# TC37XPD register map
Vendor: Infineon; Series: ATVMC; File version: 100
CPU: other r0p0, little endian, MPU, FPU, vendor SysTick, 4 interrupt priority bits
Registers are 32-bit, read-write, reset 0x0 unless marked. A register's access mark holds for its fields unless they carry their own. Offsets are from the block's base; [hi:lo] are bit positions; {n}, {i} and the like mark numbered series.

## GETH (part 5 of 7)
Base 0xF001D000
0x810 RXIPV4_GOOD_PACKETS ro — Good Received RxIPv4 Packets Count Register resetvalue={Application Reset:0x0}
  [15:0] RXIPV4GDPKT — RxIPv4 Good Packets RXIPV4GDPKT. This field indicates the number of good IPv4 datagrams received with the TCP UDP or ICMP payload. Value After Reset 0x0
0x814 RXIPV4_HEADER_ERROR_PACKETS ro — Received IPv4 Header Error Packets Count Register resetvalue={Application Reset:0x0}
  [15:0] RXIPV4HDRERRPKT — RxIPv4 Header Error Packets RXIPV4HDRERRPKT. This field indicates the number of IPv4 datagrams received with header checksum length or version mismatch errors. Value After Reset 0x0
0x818 RXIPV4_NO_PAYLOAD_PACKETS ro — Received IPv4 No Payload Packets Count Register resetvalue={Application Reset:0x0}
  [15:0] RXIPV4NOPAYPKT — RxIPv4 Payload Packets RXIPV4NOPAYPKT. This field indicates the number of IPv4 datagram packets received that did not have a TCP UDP or ICMP payload. Value After Reset 0x0
0x81C RXIPV4_FRAGMENTED_PACKETS ro — Received IPv4 Fragmented Packets Count Register resetvalue={Application Reset:0x0}
  [15:0] RXIPV4FRAGPKT — RxIPv4 Fragmented Packets RXIPV4FRAGPKT. This field indicates the number of good IPv4 datagrams received with fragmentation. Value After Reset 0x0
0x820 RXIPV4_UDP_CHECKSUM_DISABLED_PACKETS ro — Received IPv4 UPD Checksum Disabled Packets Count Register resetvalue={Application Reset:0x0}
  [15:0] RXIPV4UDSBLPKT — RxIPv4 UDP Checksum Disabled Packets RXIPV4UDSBLPKT. This field indicates the number of good IPv4 datagrams received that had a UDP payload with checksum disabled. Value After Reset 0x0
0x824 RXIPV6_GOOD_PACKETS ro — Good Received RxIPv6 Packets Count Register resetvalue={Application Reset:0x0}
  [15:0] RXIPV6GDPKT — RxIPv6 Good Packets RXIPV6GDPKT. This field indicates the number of good IPv6 datagrams received with the TCP UDP or ICMP payload. Value After Reset 0x0
0x828 RXIPV6_HEADER_ERROR_PACKETS ro — Received IPv6 Header Error Packets Count Register resetvalue={Application Reset:0x0}
  [15:0] RXIPV6HDRERRPKT — RxIPv6 Header Error Packets RXIPV6HDRERRPKT. This field indicates the number of IPv6 datagrams received with header length or version mismatch errors. Value After Reset 0x0
0x82C RXIPV6_NO_PAYLOAD_PACKETS ro — Received IPv6 No Payload Packets Count Register resetvalue={Application Reset:0x0}
  [15:0] RXIPV6NOPAYPKT — RxIPv6 Payload Packets RXIPV6NOPAYPKT. This field indicates the number of IPv6 datagram packets received that did not have a TCP UDP or ICMP payload. This includes all IPv6 datagrams with fragmentation or security extension headers. Value After Reset 0x0
0x830 RXUDP_GOOD_PACKETS ro — Good Received UDP Packets Count Register resetvalue={Application Reset:0x0}
  [15:0] RXUDPGDPKT — RxUDP Good Packets RXUDPGDPKT. This field indicates the number of good IP datagrams received with a good UDP payload. This counter is not updated when the RxIPv4 UDP Checksum Disabled Packets counter is incremented. Value After Reset 0x0
0x834 RXUDP_ERROR_PACKETS ro — Received UDP Error Packets Count Register resetvalue={Application Reset:0x0}
  [15:0] RXUDPERRPKT — RxUDP Error Packets RXUDPERRPKT. This field indicates the number of good IP datagrams received whose UDP payload has a checksum error. Value After Reset 0x0
0x838 RXTCP_GOOD_PACKETS ro — Good Received TCP Packets Count Register resetvalue={Application Reset:0x0}
  [15:0] RXTCPGDPKT — RxTCP Good Packets RXTCPGDPKT. This field indicates the number of good IP datagrams received with a good TCP payload. Value After Reset 0x0
0x83C RXTCP_ERROR_PACKETS ro — Received TCP Error Packets Count Register resetvalue={Application Reset:0x0}
  [15:0] RXTCPERRPKT — RxTCP Error Packets RXTCPERRPKT. This field indicates the number of good IP datagrams received whose TCP payload has a checksum error. Value After Reset 0x0
0x840 RXICMP_GOOD_PACKETS ro — Good Received ICMP Packets Count Register resetvalue={Application Reset:0x0}
  [15:0] RXICMPGDPKT — RxICMP Good Packets RXICMPGDPKT. This field indicates the number of good IP datagrams received with a good ICMP payload. Value After Reset 0x0
0x844 RXICMP_ERROR_PACKETS ro — Received ICMP Error Packets Count Register resetvalue={Application Reset:0x0}
  [15:0] RXICMPERRPKT — RxICMP Error Packets RXICMPERRPKT. This field indicates the number of good IP datagrams received whose ICMP payload has a checksum error. Value After Reset 0x0
0x850 RXIPV4_GOOD_OCTETS ro — Good Received IPV4 Octets Count Register resetvalue={Application Reset:0x0}
  [31:0] RXIPV4GDOCT — RxIPv4 Good Octets RXIPV4GDOCT. This field indicates the number of bytes received in good IPv4 datagrams encapsulating TCP UDP or ICMP data. Ethernet header FCS pad or IP pad bytes are not included in this counter. Value After Reset 0x0
0x854 RXIPV4_HEADER_ERROR_OCTETS ro — Received IPV4 Header Error Octets Count Register resetvalue={Application Reset:0x0}
  [31:0] RXIPV4HDRERROCT — RxIPv4 Header Error Octets RXIPV4HDRERROCT. This field indicates the number of bytes received in IPv4 datagrams with header errors checksum length version mismatch . The value in the Length field of IPv4 header is used to update this counter. Ethernet header FCS pad or IP pad bytes are not included in this counter. Value After Reset 0x0
0x858 RXIPV4_NO_PAYLOAD_OCTETS ro — Received IPV4 No Payload Octets Count Register resetvalue={Application Reset:0x0}
  [31:0] RXIPV4NOPAYOCT — RxIPv4 Payload Octets RXIPV4NOPAYOCT. This field indicates the number of bytes received in IPv4 datagrams that did not have a TCP UDP or ICMP payload. The value in the Length field of IPv4 header is used to update this counter. Ethernet header FCS pad or IP pad bytes are not included in this counter. Value After Reset 0x0
0x85C RXIPV4_FRAGMENTED_OCTETS ro — Received IPV4 Fragmented Octets Count Register resetvalue={Application Reset:0x0}
  [31:0] RXIPV4FRAGOCT — RxIPv4 Fragmented Octets RXIPV4FRAGOCT. This field indicates the number of bytes received in fragmented IPv4 datagrams. The value in the Length field of IPv4 header is used to update this counter. Ethernet header FCS pad or IP pad bytes are not included in this counter. Value After Reset 0x0
0x860 RXIPV4_UDP_CHECKSUM_DISABLE_OCTETS ro — Received IPV4 UPD Checksum Disabled Octets Count Register resetvalue={Application Reset:0x0}
  [31:0] RXIPV4UDSBLOCT — RxIPv4 UDP Checksum Disable Octets RXIPV4UDSBLOCT. This field indicates the number of bytes received in a UDP segment that had the UDP checksum disabled. This counter does not count IP Header bytes. Ethernet header FCS pad or IP pad bytes are not included in this counter. Value After Reset 0x0
0x864 RXIPV6_GOOD_OCTETS ro — Good Received IPV6 Octets Count Register resetvalue={Application Reset:0x0}
  [31:0] RXIPV6GDOCT — RxIPv6 Good Octets RXIPV6GDOCT. This field indicates the number of bytes received in good IPv6 datagrams encapsulating TCP UDP or ICMP data. Ethernet header FCS pad or IP pad bytes are not included in this counter. Value After Reset 0x0
0x868 RXIPV6_HEADER_ERROR_OCTETS ro — Received IPV6 Header Error Octets Count Register resetvalue={Application Reset:0x0}
  [31:0] RXIPV6HDRERROCT — RxIPv6 Header Error Octets RXIPV6HDRERROCT. This field indicates the number of bytes received in IPv6 datagrams with header errors length version mismatch . The value in the Length field of IPv6 header is used to update this counter. Ethernet header FCS pad or IP pad bytes are not included in this counter. Value After Reset 0x0
0x86C RXIPV6_NO_PAYLOAD_OCTETS ro — Received IPV6 No Payload Octets Count Register resetvalue={Application Reset:0x0}
  [31:0] RXIPV6NOPAYOCT — RxIPv6 Payload Octets RXIPV6NOPAYOCT. This field indicates the number of bytes received in IPv6 datagrams that did not have a TCP UDP or ICMP payload. The value in the Length field of IPv6 header is used to update this counter. Ethernet header FCS pad or IP pad bytes are not included in this counter. Value After Reset 0x0
0x870 RXUDP_GOOD_OCTETS ro — Good Received UDP Octets Count Register resetvalue={Application Reset:0x0}
  [31:0] RXUDPGDOCT — RxUDP Good Octets RXUDPGDOCT. This field indicates the number of bytes received in a good UDP segment. This counter does not count IP header bytes. Value After Reset 0x0
0x874 RXUDP_ERROR_OCTETS ro — Received UDP Error Octets Count Register resetvalue={Application Reset:0x0}
  [31:0] RXUDPERROCT — RxUDP Error Octets RXUDPERROCT. This field indicates the number of bytes received in a UDP segment that had checksum errors. This counter does not count IP header bytes. Value After Reset 0x0
0x878 RXTCP_GOOD_OCTETS ro — Good Received TCP Octets Count Register resetvalue={Application Reset:0x0}
  [31:0] RXTCPGDOCT — RxTCP Good Octets RXTCPGDOCT. This field indicates the number of bytes received in a good TCP segment. This counter does not count IP header bytes. Value After Reset 0x0
0x87C RXTCP_ERROR_OCTETS ro — Received TCP Error Octets Count Register resetvalue={Application Reset:0x0}
  [31:0] RXTCPERROCT — RxTCP Error Octets RXTCPERROCT. This field indicates the number of bytes received in a TCP segment that had checksum errors. This counter does not count IP header bytes. Value After Reset 0x0
0x880 RXICMP_GOOD_OCTETS ro — Good Received ICMP Octets Count Register resetvalue={Application Reset:0x0}
  [31:0] RXICMPGDOCT — RxICMP Good Octets RXICMPGDOCT. This field indicates the number of bytes received in a good ICMP segment. This counter does not count IP header bytes. Value After Reset 0x0
0x884 RXICMP_ERROR_OCTETS ro — Received ICMP Error Octets Count Register resetvalue={Application Reset:0x0}
  [31:0] RXICMPERROCT — RxICMP Error Octets RXICMPERROCT. This field indicates the number of bytes received in a ICMP segment that had checksum errors. This counter does not count IP header bytes. Value After Reset 0x0
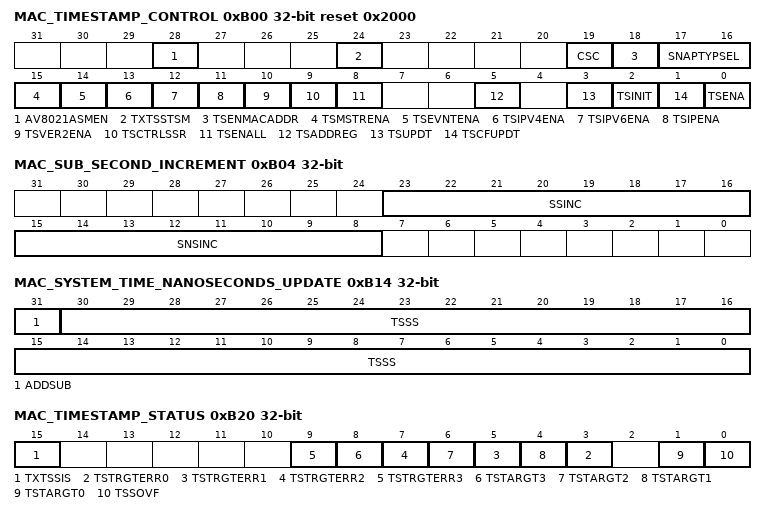
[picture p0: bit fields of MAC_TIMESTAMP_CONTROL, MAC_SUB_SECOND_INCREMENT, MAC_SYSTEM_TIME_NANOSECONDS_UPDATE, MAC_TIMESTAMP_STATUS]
0xB00 MAC_TIMESTAMP_CONTROL reset 0x2000 — MAC Timestamp Control Register resetvalue={Application Reset:0x2000}
  [28] AV8021ASMEN — AV 802.1AS Mode Enable AV8021ASMEN. When this bit is set the MAC processes only untagged PTP over Ethernet packets for providing PTP status and capturing timestamp snapshots that is IEEE 802.1AS mode of operation. When PTP offload feature is enabled for the purpose of PTP offload the transport specific field in the PTP header is generated and checked based on the value of this bit. Value After Reset 0x0
  [24] TXTSSTSM — Transmit Timestamp Status Mode TXTSSTSM. When this bit is set the MAC overwrites the earlier transmit timestamp status even if it is not read by the software. The MAC indicates this by setting the TXTSSMIS bit of the MAC TxTimestamp Status Nanoseconds register. When this bit is reset the MAC ignores the timestamp status of current packet if the timestamp status of previous packet is not read by the software. The MAC indicates this by setting the TXTSSMIS bit of the MAC TxTimestamp Status Nanoseconds register. Value After Reset 0x0
  [19] CSC — Enable checksum correction during OST for PTP over UDP IPv4 packets CSC. When this bit is set the last two bytes of PTP message sent over UDP IPv4 is updated to keep the UDP checksum correct for changes made to origin timestamp and or correction field as part of one step timestamp operation. The application shall form the packet with these two dummy bytes. When reset no updates are done to keep the UDP checksum correct. The application shall form the packet with UDP checksum set to 0. Value After Reset 0x0
  [18] TSENMACADDR — Enable MAC Address for PTP Packet Filtering TSENMACADDR. When this bit is set the DA MAC address that matches any MAC Address register is used to filter the PTP packets when PTP is directly sent over Ethernet. When this bit is set received PTP packets with DA containing a special multicast or unicast address that matches the one programmed in MAC address registers are considered for processing as indicated below when PTP is directly sent over Ethernet. For normal time stamping operation MAC address registers 0 to 31 is considered for unicast destination address matching. For PTP offload only MAC address register 0 is considered for unicast destination address matching. Value After Reset 0x0
  [17:16] SNAPTYPSEL — Select PTP packets for Taking Snapshots SNAPTYPSEL. These bits along with Bits 15 and 14 decide the set of PTP packet types for which snapshot needs to be taken. The encoding is given in Timestamp Snapshot Dependency on Register Bits Table. Value After Reset 0x0
  [15] TSMSTRENA — Enable Snapshot for Messages Relevant to Master TSMSTRENA. When this bit is set the snapshot is taken only for the messages that are relevant to the master node. Otherwise the snapshot is taken for the messages relevant to the slave node. Value After Reset 0x0
  [14] TSEVNTENA — Enable Timestamp Snapshot for Event Messages TSEVNTENA. When this bit is set the timestamp snapshot is taken only for event messages SYNC Delay Req Pdelay Req or Pdelay Resp . When this bit is reset the snapshot is taken for all messages except Announce Management and Signaling. For more information about the timestamp snapshots see Timestamp Snapshot Dependency on Register Bits Table. Value After Reset 0x0
  [13] TSIPV4ENA — Enable Processing of PTP Packets Sent over IPv4 UDP TSIPV4ENA. When this bit is set the MAC receiver processes the PTP packets encapsulated in IPv4 UDP packets. When this bit is reset the MAC ignores the PTP transported over IPv4 UDP packets. This bit is set by default. Value After Reset 0x1
  [12] TSIPV6ENA — Enable Processing of PTP Packets Sent over IPv6 UDP TSIPV6ENA. When this bit is set the MAC receiver processes the PTP packets encapsulated in IPv6 UDP packets. When this bit is clear the MAC ignores the PTP transported over IPv6 UDP packets. Value After Reset 0x0
  [11] TSIPENA — Enable Processing of PTP over Ethernet Packets TSIPENA. When this bit is set the MAC receiver processes the PTP packets encapsulated directly in the Ethernet packets. When this bit is reset the MAC ignores the PTP over Ethernet packets. Value After Reset 0x0
  [10] TSVER2ENA — Enable PTP Packet Processing for Version 2 Format TSVER2ENA. When this bit is set the IEEE 1588 version 2 format is used to process the PTP packets. When this bit is reset the IEEE 1588 version 1 format is used to process the PTP packets. The IEEE 1588 formats are described in PTP Processing and Control . Value After Reset 0x0
  [9] TSCTRLSSR — Timestamp Digital or Binary Rollover Control TSCTRLSSR. When this bit is set the Timestamp Low register rolls over after 0x3B9A C9FF value that is 1 nanosecond accuracy and increments the timestamp High seconds. When this bit is reset the rollover value of sub second register is 0x7FFF FFFF. The sub second increment must be programmed correctly depending on the PTP reference clock frequency and the value of this bit. Value After Reset 0x0
  [8] TSENALL — Enable Timestamp for All Packets TSENALL. When this bit is set the timestamp snapshot is enabled for all packets received by the MAC. Value After Reset 0x0
  [5] TSADDREG — Update Addend Register TSADDREG. When this bit is set the content of the Timestamp Addend register is updated in the PTP block for fine correction. This bit is cleared when the update is complete. This bit should be zero before it is set. Access restriction applies. Setting 1 sets. Self cleared. Setting 0 has no effect. Value After Reset 0x0
  [3] TSUPDT — Update Timestamp TSUPDT. When this bit is set the system time is updated added or subtracted with the value specified in MAC System Time Seconds Update and MAC System Time Nanoseconds Update. This bit should be zero before updating it. This bit is reset when the update is complete in hardware. The Timestamp Higher Word register if enabled during core configuration is not updated. Access restriction applies. Setting 1 sets. Self cleared. Setting 0 has no effect. Value After Reset 0x0
  [2] TSINIT — Initialize Timestamp TSINIT. When this bit is set the system time is initialized overwritten with the value specified in the MAC Register 80 System Time Seconds Update Register and MAC Register 81 System Time Nanoseconds Update Register . This bit should be zero before it is updated. This bit is reset when the initialization is complete. The Timestamp Higher Word register if enabled during core configuration can only be initialized. Access restriction applies. Setting 1 sets. Self cleared. Setting 0 has no effect. Value After Reset 0x0
  [1] TSCFUPDT — Fine or Coarse Timestamp Update TSCFUPDT. When this bit is set the Fine method is used to update system timestamp. When this bit is reset Coarse method is used to update the system timestamp. Value After Reset 0x0
  [0] TSENA — Enable Timestamp TSENA. When this bit is set the timestamp is added for Transmit and Receive packets. When disabled timestamp is not added for transmit and receive packets and the Timestamp Generator is also suspended. You need to initialize the Timestamp system time after enabling this mode. On the Receive side the MAC processes the 1588 packets only if this bit is set. Value After Reset 0x0
0xB04 MAC_SUB_SECOND_INCREMENT — MAC Sub Second Increment Register resetvalue={Application Reset:0x0}
  [23:16] SSINC — Sub second Increment Value SSINC. The value programmed in this field is accumulated every clock cycle of clk ptp i with the contents of the sub second register. For example when the PTP clock is 50 MHz period is 20 ns you should program 20 0x14 when the System Time Nanoseconds register has an accuracy of 1 ns Bit 9 TSCTRLSSR is set in MAC Timestamp Control . When TSCTRLSSR is clear the Nanoseconds register has a resolution of 0.465 ns. In this case you should program a value of 43 0x2B which is derived by 20 ns 0.465. Value After Reset 0x0
  [15:8] SNSINC — Sub nanosecond Increment Value SNSINC. This field contains the sub nanosecond increment value represented in nanoseconds multiplied by 2 8. This value is accumulated with the sub nanoseconds field of the subsecond register. For example when TSCTRLSSR field in the MAC Timestamp Control register is set. and if the required increment is 5.3ns then SSINC should be 0x05 and SNSINC should be 0x4C. Value After Reset 0x0
0xB08 MAC_SYSTEM_TIME_SECONDS ro — MAC System Time Seconds Register resetvalue={Application Reset:0x0}
  [31:0] TSS — Timestamp Second TSS. The value in this field indicates the current value in seconds of the System Time maintained by the MAC. Value After Reset 0x0
0xB0C MAC_SYSTEM_TIME_NANOSECONDS ro — MAC System Time Nanoseconds Register resetvalue={Application Reset:0x0}
  [30:0] TSSS — Timestamp Sub Seconds TSSS. The value in this field has the sub second representation of time with an accuracy of 0.46 ns. When Bit 9 is set in MAC Timestamp Control each bit represents 1 ns. The maximum value is 0x3B9A C9FF after which it rolls over to zero. Value After Reset 0x0
0xB10 MAC_SYSTEM_TIME_SECONDS_UPDATE — MAC System Time Seconds Update Register resetvalue={Application Reset:0x0}
  [31:0] TSS — Timestamp Seconds TSS. The value in this field is the seconds part of the update. When ADDSUB is reset this field must be programmed with the seconds part of the update value. When ADDSUB is set this field must be programmed with the complement of the seconds part of the update value. For example if 2.000000001 seconds need to be subtracted from the system time the TSS field in the MAC Timestamp Seconds Update register must be 0xFFFF FFFE that is 2 32 2 . Value After Reset 0x0
0xB14 MAC_SYSTEM_TIME_NANOSECONDS_UPDATE — MAC System Time Nanoseconds Update Register resetvalue={Application Reset:0x0}
  [31] ADDSUB — Add or Subtract Time ADDSUB. When this bit is set the time value is subtracted with the contents of the update register. When this bit is reset the time value is added with the contents of the update register. Value After Reset 0x0
  [30:0] TSSS — Timestamp Sub Seconds TSSS. The value in this field is the sub seconds part of the update. When ADDSUB is reset this field must be programmed with the sub seconds part of the update value with an accuracy based on the TSCTRLSSR bit of the MAC Timestamp Control register. When ADDSUB is set this field must be programmed with the complement of the sub seconds part of the update value as described below. When TSCTRLSSR bit in MAC Timestamp Control is set the programmed value must be 10 9 lt sub second value gt . When TSCTRLSSR bit in MAC Timestamp Control is reset the programmed value must be 2 31 lt sub second value gt . When the TSCTRLSSR bit is reset in the MAC Timestamp Control register each bit represents an accuracy of 0.46 ns. When the TSCTRLSSR bit is set in the MAC Timestamp Control register each bit represents 1 ns and the programmed value should not exceed 0x3B9A C9FF. For example if 2.000000001 seconds need to be subtracted from the system time then the TSSS field in the MAC Timestamp Nanoseconds Update register must be 0x7FFF FFFF that is 2 31 1 when TSCTRLSSR bit in MAC Timestamp Control is reset and 0x3B9A C9FF that is 10 9 1 when TSCTRLSSR bit in MAC Timestamp Control is set. Value After Reset 0x0
0xB18 MAC_TIMESTAMP_ADDEND — MAC Timestamp Addend Register resetvalue={Application Reset:0x0}
  [31:0] TSAR — Timestamp Addend Register TSAR. This field indicates the 32 bit time value to be added to the Accumulator register to achieve time synchronization. Value After Reset 0x0
0xB1C MAC_SYSTEM_TIME_HIGHER_WORD_SECONDS — MAC System Time Higher Word Seconds Register resetvalue={Application Reset:0x0}
  [15:0] TSHWR — Timestamp Higher Word Register TSHWR. This field contains the most significant 16 bits of timestamp seconds value. This register is optional. You can add this register by selecting the Add IEEE 1588 Higher Word Register option. This register is directly written to initialize the value and it is incremented when there is an overflow from 32 bits of the System Time Seconds register. Access restriction applies. Updated based on the event. Setting 1 sets. Setting 0 clears. Value After Reset 0x0
0xB20 MAC_TIMESTAMP_STATUS ro — MAC Timestamp Status Register resetvalue={Application Reset:0x0}
  [15] TXTSSIS — Tx Timestamp Status Interrupt Status TXTSSIS. When drop transmit status is enabled in MTL this bit is set when the captured transmit timestamp is updated in the MAC Tx Timestamp Status Nanoseconds and MAC Tx Timestamp Status Seconds registers. When PTP offload feature is enabled this bit is set when the captured transmit timestamp is updated in the MAC Tx Timestamp Status Nanoseconds and MAC Tx Timestamp Status Seconds registers for PTO generated Delay Request and Pdelay request packets. This bit is cleared when the MAC Tx Timestamp Status Seconds register is read or write to MAC Tx Timestamp Status Seconds register when RCWE bit of MAC CSR SW Ctrl register is set . Value After Reset 0x0
  [2n+3] TSTRGTERR{n} (n=0..3) — Timestamp Target Time Error TSTRGTERR{n}. This bit is set when the latest target time programmed in the MAC PPS{n} Target Time Seconds and MAC PPS{n} Target Time Nanoseconds registers elapses. This bit is cleared when the application reads this bit. Access restriction applies. Clears on read or this bit is written to 1 when RCWE bit in MAC CSR SW Ctrl register is set . Self set to 1 on internal event. Value After Reset 0x0
  [8] TSTARGT3 — Timestamp Target Time Reached for Target Time PPS3 TSTARGT3. When this bit is set it indicates that the value of system time is greater than or equal to the value specified in the MAC PPS3 Target Time Seconds and MAC PPS3 Target Time Nanoseconds registers. Access restriction applies. Clears on read or this bit is written to 1 when RCWE bit in MAC CSR SW Ctrl register is set . Self set to 1 on internal event. Value After Reset 0x0
  [6] TSTARGT2 — Timestamp Target Time Reached for Target Time PPS2 TSTARGT2. When set this bit indicates that the value of system time is greater than or equal to the value specified in the MAC PPS2 Target Time Seconds and MAC PPS2 Target Time Nanoseconds registers. Access restriction applies. Clears on read or this bit is written to 1 when RCWE bit in MAC CSR SW Ctrl register is set . Self set to 1 on internal event. Value After Reset 0x0
  [4] TSTARGT1 — Timestamp Target Time Reached for Target Time PPS1 TSTARGT1. When set this bit indicates that the value of system time is greater than or equal to the value specified in the MAC PPS1 Target Time Seconds and MAC PPS1 Target Time Nanoseconds registers. Access restriction applies. Clears on read or this bit is written to 1 when RCWE bit in MAC CSR SW Ctrl register is set . Self set to 1 on internal event. Value After Reset 0x0
  [1] TSTARGT0 — Timestamp Target Time Reached TSTARGT0. When set this bit indicates that the value of system time is greater than or equal to the value specified in the MAC PPS0 Target Time Seconds and MAC PPS0 Target Time Nanoseconds registers. Access restriction applies. Clears on read or this bit is written to 1 when RCWE bit in MAC CSR SW Ctrl register is set . Self set to 1 on internal event. Value After Reset 0x0
  [0] TSSOVF — Timestamp Seconds Overflow TSSOVF. When this bit is set it indicates that the seconds value of the timestamp when supporting version 2 format has overflowed beyond 32 hFFFF FFFF. Access restriction applies. Clears on read or this bit is written to 1 when RCWE bit in MAC CSR SW Ctrl register is set . Self set to 1 on internal event. Value After Reset 0x0
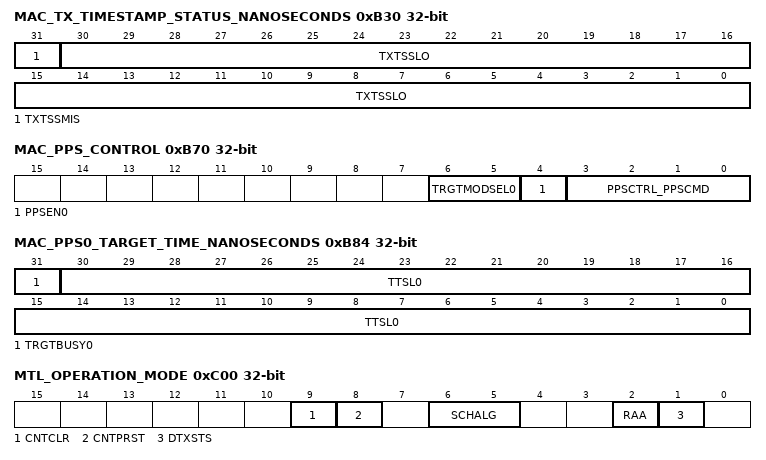
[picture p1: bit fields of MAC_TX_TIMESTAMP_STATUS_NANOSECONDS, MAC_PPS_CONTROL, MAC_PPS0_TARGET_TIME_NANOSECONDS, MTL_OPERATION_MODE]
0xB30 MAC_TX_TIMESTAMP_STATUS_NANOSECONDS ro — MAC Transmit Timestamp Nanoseconds Status Register resetvalue={Application Reset:0x0}
  [31] TXTSSMIS — Transmit Timestamp Status Missed TXTSSMIS. When this bit is set it indicates one of the following The timestamp of the current packet is ignored if TXTSSTSM bit of the MAC Timestamp Control register is reset The timestamp of the previous packet is overwritten with timestamp of the current packet if TXTSSTSM bit of the MAC Timestamp Control register is set. Access restriction applies. Clears on read. Self set to 1 on internal event. Value After Reset 0x0
  [30:0] TXTSSLO — Transmit Timestamp Status Low TXTSSLO. This field contains the 31 bits of the Nanoseconds field of the Transmit packet s captured timestamp. Value After Reset 0x0
0xB34 MAC_TX_TIMESTAMP_STATUS_SECONDS ro — MAC Transmit Timestamp Seconds Status Register resetvalue={Application Reset:0x0}
  [31:0] TXTSSHI — Transmit Timestamp Status High TXTSSHI. This field contains the lower 32 bits of the Seconds field of Transmit packet s captured timestamp. Value After Reset 0x0
0xB50 MAC_TIMESTAMP_INGRESS_ASYM_CORR — MAC Timestamp Ingress Asymmetry Correction Register resetvalue={Application Reset:0x0}
  [31:0] OSTIAC — One Step Timestamp Ingress Asymmetry Correction OSTIAC. This field contains the ingress path asymmetry value to be added to correctionField of Pdelay Resp PTP packet. The programmed value should be in units of nanoseconds and multiplied by 2 16. For example 2.5 ns is represented as 0x00028000. The value can also be negative which is represented in 2 s complement form with bit 31 representing the sign bit. Value After Reset 0x0
0xB54 MAC_TIMESTAMP_EGRESS_ASYM_CORR — MAC Timestamp Egress Asymmetry Correction Register resetvalue={Application Reset:0x0}
  [31:0] OSTEAC — One Step Timestamp Egress Asymmetry Correction OSTEAC. This field contains the egress path asymmetry value to be subtracted from correctionField of Pdelay Resp PTP packet. The programmed value must be the negated value in units of nanoseconds multiplied by 2 16. For example if the required correction is 2.5 ns the programmed value must be 0xFFFD 8000 which is the 2 s complement of 0x0002 8000 2.5 216 . Similarly if the required correction is 3.3 ns the programmed value is 0x0003 4CCC 3.3 216 . Value After Reset 0x0
0xB58 MAC_TIMESTAMP_INGRESS_CORR_NANOSECOND — MAC Timestamp Ingress Correction Nanoseconds Register resetvalue={Application Reset:0x0}
  [31:0] TSIC — Timestamp Ingress Correction TSIC. This field contains the ingress path correction value as defined by the Ingress Correction expression. Value After Reset 0x0
0xB5C MAC_TIMESTAMP_EGRESS_CORR_NANOSECOND — MAC Timestamp Egress Correction Nanoseconds Register resetvalue={Application Reset:0x0}
  [31:0] TSEC — Timestamp Egress Correction TSEC. This field contains the nanoseconds part of the egress path correction value as defined by the Egress Correction expression. Value After Reset 0x0
0xB60 MAC_TIMESTAMP_INGRESS_CORR_SUBNANOSEC — MAC Timestamp Ingress Correction Subnanoseconds Register resetvalue={Application Reset:0x0}
  [15:8] TSICSNS — Timestamp Ingress Correction sub nanoseconds TSICSNS. This field contains the sub nanoseconds part of the ingress path correction value as defined by the Ingress Correction expression. Value After Reset 0x0
0xB64 MAC_TIMESTAMP_EGRESS_CORR_SUBNANOSEC — MAC Timestamp Egress Correction Subnanoseconds Register resetvalue={Application Reset:0x0}
  [15:8] TSECSNS — Timestamp Egress Correction sub nanoseconds TSECSNS. This field contains the sub nanoseconds part of the egress path correction value as defined by the Egress Correction expression. Value After Reset 0x0
0xB70 MAC_PPS_CONTROL — MAC PPS Control Register resetvalue={Application Reset:0x0}
  [6:5] TRGTMODSEL0 — Target Time Register Mode for PPS0 Output TRGTMODSEL0. This field indicates the Target Time registers MAC PPS0 Target Time Seconds and MAC PPS0 Target Time Nanoseconds mode for PPS0 output signal Value After Reset 0x0
  [4] PPSEN0 — Flexible PPS Output Mode Enable PPSEN0. When this bit is set Bits 3 0 function as PPSCMD. When this bit is reset Bits 3 0 function as PPSCTRL Fixed PPS mode . Value After Reset 0x0
  [3:0] PPSCTRL_PPSCMD — Flexible PPS Output ptp pps o 0 Control PPSCTRL PPSCMD. This field controls the frequency of the PPS0 output ptp pps o 0 signal. The default value of PPSCTRL is 0000 and the PPS output is 1 pulse of width clk ptp i every second. For other values of PPSCTRL the PPS output becomes a generated clock of following frequencies LOST SEQUENCE DEFINITION Access restriction applies. Setting 1 sets. Self cleared. Setting 0 has no effect. Value After Reset 0x0
0xB80 MAC_PPS0_TARGET_TIME_SECONDS — MAC PPS 0 Target Time Seconds Register resetvalue={Application Reset:0x0}
  [31:0] TSTRH0 — PPS Target Time Seconds Register TSTRH0. This field stores the time in seconds. When the timestamp value matches or exceeds both Target Timestamp registers the MAC starts or stops the PPS signal output and generates an interrupt if enabled based on Target Time mode selected for the corresponding PPS output in the MAC PPS Control register. Value After Reset 0x0
0xB84 MAC_PPS0_TARGET_TIME_NANOSECONDS — MAC PPS 0 Target Time Nanoeconds Register resetvalue={Application Reset:0x0}
  [31] TRGTBUSY0 — PPS Target Time Register Busy TRGTBUSY0. The MAC sets this bit when the PPSCMD0 field in the MAC PPS Control register is programmed to 010 or 011. Programming the PPSCMD0 field to 010 or 011 instructs the MAC to synchronize the Target Time Registers to the PTP clock domain. The MAC clears this bit after synchronizing the Target Time Registers to the PTP clock domain The application must not update the Target Time Registers when this bit is read as 1. Otherwise the synchronization of the previous programmed time gets corrupted. Value After Reset 0x0
  [30:0] TTSL0 — Target Time Low for PPS Register TTSL0. This register stores the time in signed nanoseconds. When the value of the timestamp matches the value in both Target Timestamp registers the MAC starts or stops the PPS signal output and generates an interrupt if enabled based on the TRGTMODSEL0 field Bits 6 5 in MAC PPS Control. When the TSCTRLSSR bit is reset in the MAC Timestamp Control register this value should be time in ns 0.465 . The actual start or stop time of the PPS signal output may have an error margin up to one unit of sub second increment value. When the TSCTRLSSR bit is set in the MAC Timestamp Control register this value should not exceed 0x3B9A C9FF. The actual start or stop time of the PPS signal output may have an error margin up to one unit of sub second increment value. Access restriction applies. Setting 1 sets. Self cleared. Setting 0 has no effect. Value After Reset 0x0
0xB88 MAC_PPS0_INTERVAL — MAC PPS 0 Interval Register resetvalue={Application Reset:0x0}
  [31:0] PPSINT0 — PPS Output Signal Interval PPSINT0. These bits store the interval between the rising edges of PPS0 signal output. The interval is stored in terms of number of units of sub second increment value. You need to program one value less than the required interval. For example if the PTP reference clock is 50 MHz period of 20 ns and desired interval between the rising edges of PPS0 signal output is 100 ns that is 5 units of sub second increment value you should program value 4 5 1 in this register. Value After Reset 0x0
0xB8C MAC_PPS0_WIDTH — MAC PPS 0 Width Register resetvalue={Application Reset:0x0}
  [31:0] PPSWIDTH0 — PPS Output Signal Width PPSWIDTH0. These bits store the width between the rising edge and corresponding falling edge of PPS0 signal output. The width is stored in terms of number of units of sub second increment value. You need to program one value less than the required interval. For example if PTP reference clock is 50 MHz period of 20 ns and width between the rising and corresponding falling edges of PPS0 signal output is 80 ns that is four units of sub second increment value you should program value 3 4 1 in this register. Note The value programmed in this register must be lesser than the value programmed in MAC PPS0 Interval. Value After Reset 0x0
0xC00 MTL_OPERATION_MODE — MTL Operation Mode Register resetvalue={Application Reset:0x0}
  [9] CNTCLR — Counters Reset CNTCLR. When this bit is set all counters are reset. This bit is cleared automatically after 1 clock cycle. If this bit is set along with CNTPRESET bit CNTPRESET has precedence. Access restriction applies. Setting 1 sets. Self cleared. Setting 0 has no effect. Value After Reset 0x0
  [8] CNTPRST — Counters Preset CNTPRST. When this bit is set MTL TxQ 0 7 Underflow register is initialized preset to 12 h7F0. Missed Packet and Overflow Packet counters in MTL RxQ 0 7 Missed Packet Overflow Cnt register is initialized preset to 12 h7F0. Access restriction applies. Setting 1 sets. Self cleared. Setting 0 has no effect. Value After Reset 0x0
  [6:5] SCHALG — Tx Scheduling Algorithm SCHALG. This field indicates the algorithm for Tx scheduling Value After Reset 0x0
  [2] RAA — Receive Arbitration Algorithm RAA. This field is used to select the arbitration algorithm for the Rx side. Queue 0 has the lowest priority and the last queue has the highest priority. Value After Reset 0x0
  [1] DTXSTS — Drop Transmit Status DTXSTS. When this bit is set the Tx packet status received from the MAC is dropped in the MTL. When this bit is reset the Tx packet status received from the MAC is forwarded to the application. Value After Reset 0x0
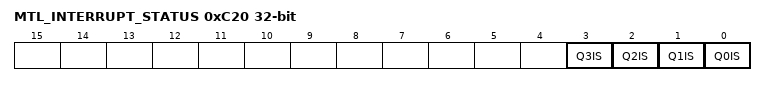
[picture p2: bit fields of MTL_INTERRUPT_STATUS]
0xC20 MTL_INTERRUPT_STATUS ro — MTL Interrupt Status Register resetvalue={Application Reset:0x0}
  [3] Q3IS — Queue 3 Interrupt status Q3IS. This bit indicates that there is an interrupt from Queue 3. To reset this bit the application must read the MTL Q3 Interrupt Control Status register to get the exact cause of the interrupt and clear its source. Value After Reset 0x0
  [2] Q2IS — Queue 2 Interrupt status Q2IS. This bit indicates that there is an interrupt from Queue 2. To reset this bit the application must read the MTL Q2 Interrupt Control Status register to get the exact cause of the interrupt and clear its source. Value After Reset 0x0
  [1] Q1IS — Queue 1 Interrupt status Q1IS. This bit indicates that there is an interrupt from Queue 1. To reset this bit the application must read the MTL Q1 Interrupt Control Status register to get the exact cause of the interrupt and clear its source. Value After Reset 0x0
  [0] Q0IS — Queue 0 Interrupt status Q0IS. This bit indicates that there is an interrupt from Queue 0. To reset this bit the application must read Queue 0 Interrupt Control and Status register to get the exact cause of the interrupt and clear its source. Value After Reset 0x0
